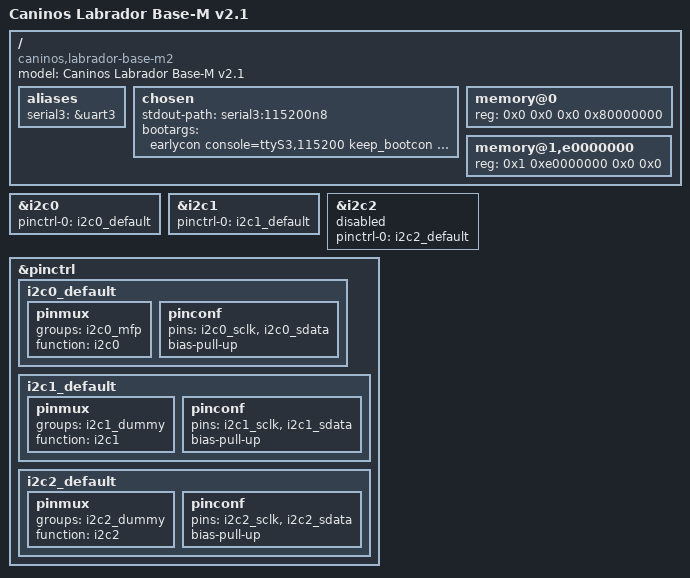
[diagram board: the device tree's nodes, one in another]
// SPDX-License-Identifier: (GPL-2.0+ OR MIT)
/*
 * Copyright (c) 2020 Matheus Castello
 */

/dts-v1/;

#include "s700-labrador-v3.dtsi"

/ {
	compatible = "caninos,labrador-base-m2", "actions,s700";
	model = "Caninos Labrador Base-M v2.1";

	aliases {
		serial3 = &uart3;
	};

	chosen {
		stdout-path = "serial3:115200n8";
		bootargs = "earlycon console=ttyS3,115200 keep_bootcon console=tty0 root=/dev/mmcblk2p1 rw rootwait no_console_suspend";
	};

	memory@0 {
		device_type = "memory";
		reg = <0x0 0x0 0x0 0x80000000>;
	};

	memory@1,e0000000 {
		device_type = "memory";
		reg = <0x1 0xe0000000 0x0 0x0>;
	};
};

&i2c0 {
	status = "okay";
	pinctrl-names = "default";
	pinctrl-0 = <&i2c0_default>;
};

&i2c1 {
	status = "okay";
	pinctrl-names = "default";
	pinctrl-0 = <&i2c1_default>;
};

&i2c2 {
	status = "disabled";
	pinctrl-names = "default";
	pinctrl-0 = <&i2c2_default>;
};

&pinctrl {
	i2c0_default: i2c0_default {
		pinmux {
			groups = "i2c0_mfp";
			function = "i2c0";
		};
		pinconf {
			pins = "i2c0_sclk", "i2c0_sdata";
			bias-pull-up;
		};
	};

	i2c1_default: i2c1_default {
		pinmux {
			groups = "i2c1_dummy";
			function = "i2c1";
		};
		pinconf {
			pins = "i2c1_sclk", "i2c1_sdata";
			bias-pull-up;
		};
	};

	i2c2_default: i2c2_default {
		pinmux {
			groups = "i2c2_dummy";
			function = "i2c2";
		};
		pinconf {
			pins = "i2c2_sclk", "i2c2_sdata";
			bias-pull-up;
		};
	};
};
